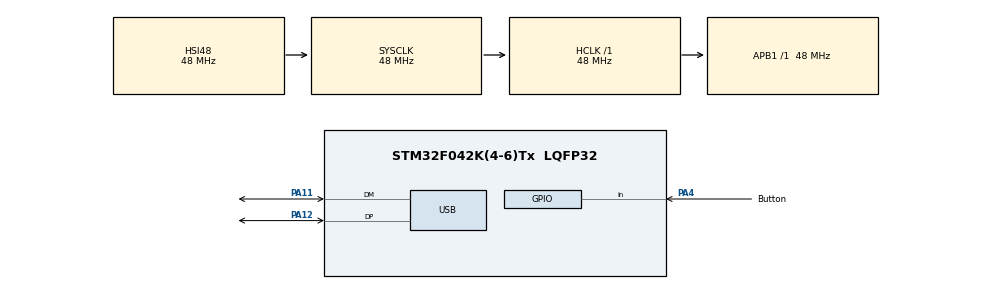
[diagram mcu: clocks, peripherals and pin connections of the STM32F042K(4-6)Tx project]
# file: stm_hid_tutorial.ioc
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Mcu.Family=STM32F0
Mcu.Name=STM32F042K(4-6)Tx
Mcu.Package=LQFP32
NVIC.USB_IRQn=true\:0\:0\:false\:false\:true\:false\:true\:true
PA11.Mode=Device
PA11.Signal=USB_DM
PA12.Mode=Device
PA12.Signal=USB_DP
PA4.GPIO_Label=Button
PA4.GPIO_PuPd=GPIO_PULLDOWN
PA4.Signal=GPIO_Input
ProjectManager.HeapSize=0x200
ProjectManager.StackSize=0x400
ProjectManager.TargetToolchain=STM32CubeIDE
RCC.AHBFreq_Value=48000000
RCC.APB1Freq_Value=48000000
RCC.APB1TimFreq_Value=48000000
RCC.HCLKFreq_Value=48000000
RCC.SYSCLKFreq_VALUE=48000000
RCC.SYSCLKSource=RCC_SYSCLKSOURCE_HSI48
USB_DEVICE.CLASS_NAME_FS=HID
USB_DEVICE.PID_HID_FS=0x0ce7
USB_DEVICE.VID=0x54c
USB_DEVICE.VirtualMode=Hid
USB_DEVICE.VirtualModeFS=Hid_FS
VP_USB_DEVICE_VS_USB_DEVICE_HID_FS.Mode=HID_FS
board=custom

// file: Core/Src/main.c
/* USER CODE BEGIN Header */
/**
  ******************************************************************************
  * @file           : main.c
  * @brief          : Main program body
  ******************************************************************************
  * @attention
  *
  * Copyright (c) 2024 STMicroelectronics.
  * All rights reserved.
  *
  * This software is licensed under terms that can be found in the LICENSE file
  * in the root directory of this software component.
  * If no LICENSE file comes with this software, it is provided AS-IS.
  *
  ******************************************************************************
  */
/* USER CODE END Header */
#include "main.h"
#include "usb_device.h"

/* USER CODE BEGIN Includes */
#include "usbd_hid.h"
/* USER CODE END Includes */

/* USER CODE BEGIN PV */
extern USBD_HandleTypeDef hUsbDeviceFS;
uint8_t buffer[] = {0, 0 ,0};
uint8_t zero[] = {0, 0, 0};
uint8_t num = 0;
uint8_t temp_num = 0;
/* USER CODE END PV */

void SystemClock_Config(void);
static void MX_GPIO_Init(void);

int main(void)
{

  /* MCU Configuration--------------------------------------------------------*/

  /* Reset of all peripherals, Initializes the Flash interface and the Systick. */
  HAL_Init();

  /* Configure the system clock */
  SystemClock_Config();

  /* USER CODE BEGIN SysInit */
//	0x05, 0x01,        // Usage Page (Generic Desktop Ctrls)
//	0x09, 0x05,        // Usage (Game Pad)
//	0xA1, 0x01,        // Collection (Application)
//	0x85, 0x01,        //   Report ID (1)
//	0x05, 0x09,        //   Usage Page (Button)
//	0x19, 0x01,        //   Usage Minimum (0x01)
//	0x29, 0x0F,        //   Usage Maximum (0x0F)
//	0x15, 0x00,        //   Logical Minimum (0)
//	0x25, 0x01,        //   Logical Maximum (1)
//	0x75, 0x01,        //   Report Size (1)
//	0x95, 0x0F,        //   Report Count (16)
//	0x81, 0x02,        //   Input (Data,Var,Abs,No Wrap,Linear,Preferred State,No Null Position)
//	0xC0,              // End Collection
// // 25 bytes
  /* USER CODE END SysInit */

  /* Initialize all configured peripherals */
  MX_GPIO_Init();
  MX_USB_DEVICE_Init();
  /* USER CODE BEGIN 2 */
//  buffer[2] = 0x1;

  /* USER CODE END 2 */

  /* Infinite loop */
  while (1)
  {

    /* USER CODE BEGIN 3 */
	  temp_num = num;
	  buffer[(uint8_t) num / 8] |= 0x1 << (num % 8);
	  if (HAL_GPIO_ReadPin(GPIOA, Button_Pin) == GPIO_PIN_SET) {
		  USBD_HID_SendReport(&hUsbDeviceFS, buffer, sizeof(buffer));
		  HAL_Delay(100);
		  num++;
	  }
	  else {
		  USBD_HID_SendReport(&hUsbDeviceFS, zero, sizeof(zero));
		  HAL_Delay(100);
	  }
	  buffer[(uint8_t) temp_num / 8] &= ~(0x1 << (temp_num % 8));
	  if (num > 16) {
		  num = 0;
	  }
  }
  /* USER CODE END 3 */
}

void SystemClock_Config(void)
{
  RCC_OscInitTypeDef RCC_OscInitStruct = {0};
  RCC_ClkInitTypeDef RCC_ClkInitStruct = {0};
  RCC_PeriphCLKInitTypeDef PeriphClkInit = {0};

  /** Initializes the RCC Oscillators according to the specified parameters
  * in the RCC_OscInitTypeDef structure.
  */
  RCC_OscInitStruct.OscillatorType = RCC_OSCILLATORTYPE_HSI48;
  RCC_OscInitStruct.HSI48State = RCC_HSI48_ON;
  RCC_OscInitStruct.PLL.PLLState = RCC_PLL_NONE;
  if (HAL_RCC_OscConfig(&RCC_OscInitStruct) != HAL_OK)
  {
    Error_Handler();
  }

  /** Initializes the CPU, AHB and APB buses clocks
  */
  RCC_ClkInitStruct.ClockType = RCC_CLOCKTYPE_HCLK|RCC_CLOCKTYPE_SYSCLK
                              |RCC_CLOCKTYPE_PCLK1;
  RCC_ClkInitStruct.SYSCLKSource = RCC_SYSCLKSOURCE_HSI48;
  RCC_ClkInitStruct.AHBCLKDivider = RCC_SYSCLK_DIV1;
  RCC_ClkInitStruct.APB1CLKDivider = RCC_HCLK_DIV1;

  if (HAL_RCC_ClockConfig(&RCC_ClkInitStruct, FLASH_LATENCY_1) != HAL_OK)
  {
    Error_Handler();
  }
  PeriphClkInit.PeriphClockSelection = RCC_PERIPHCLK_USB;
  PeriphClkInit.UsbClockSelection = RCC_USBCLKSOURCE_HSI48;

  if (HAL_RCCEx_PeriphCLKConfig(&PeriphClkInit) != HAL_OK)
  {
    Error_Handler();
  }
}

static void MX_GPIO_Init(void)
{
  GPIO_InitTypeDef GPIO_InitStruct = {0};

  /* GPIO Ports Clock Enable */
  __HAL_RCC_GPIOA_CLK_ENABLE();

  /*Configure GPIO pin : Button_Pin */
  GPIO_InitStruct.Pin = Button_Pin;
  GPIO_InitStruct.Mode = GPIO_MODE_INPUT;
  GPIO_InitStruct.Pull = GPIO_PULLDOWN;
  HAL_GPIO_Init(Button_GPIO_Port, &GPIO_InitStruct);

}

void Error_Handler(void)
{
  __disable_irq();
  while (1)
  {
  }
}
